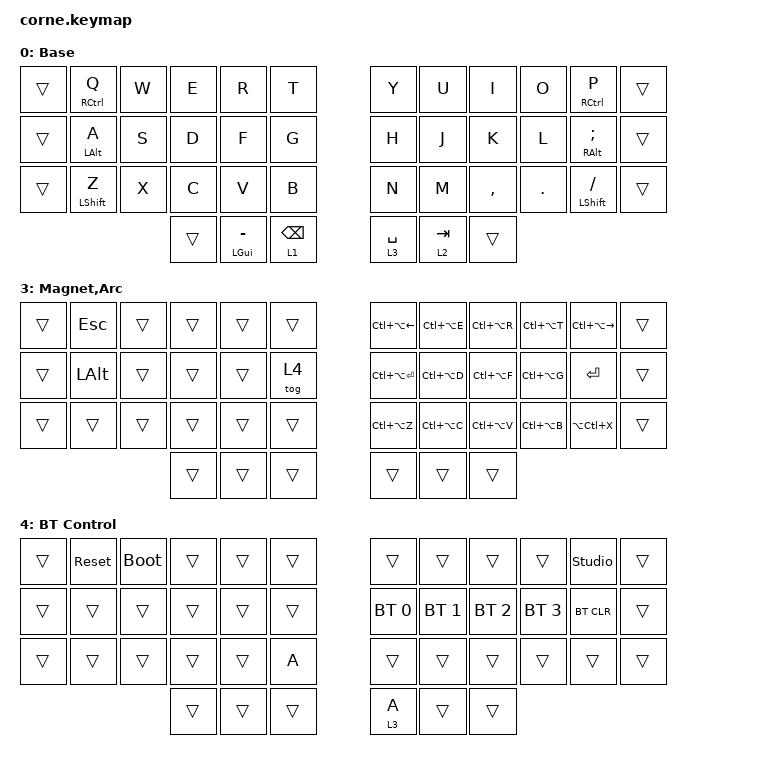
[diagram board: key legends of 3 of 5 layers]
/*
 * Copyright (c) 2020 The ZMK Contributors
 *
 * SPDX-License-Identifier: MIT
 */
//Layers 

#define Base 0
#define Lower 1
#define Raise 2
#define Funct 3

// #define block
// #define SCSH &kp LS(LG(NUMBER_4))

#include <behaviors.dtsi>
#include <dt-bindings/zmk/bt.h>
#include <dt-bindings/zmk/keys.h>

&mt {
    tapping-term-ms = <150>;

    // require-prior-idle-ms = <50>;
};

&lt {
    tapping-term-ms = <150>;

    //require-prior-idle-ms = <125>; 
};

/ {
    behaviors {
        lslc: lslc {
            compatible = "zmk,behavior-tap-dance";
            label = "LSLC";
            #binding-cells = <0>;
            tapping-term-ms = <200>;
            bindings = <&kp LEFT_SHIFT>, <&kp LCTRL>;
        };

        rsra: rsra {
            compatible = "zmk,behavior-tap-dance";
            label = "RSRA";
            #binding-cells = <0>;
            tapping-term-ms = <200>;
            bindings = <&kp RIGHT_SHIFT>, <&kp RALT>;
        };

        long_MT: long_MT {
            compatible = "zmk,behavior-hold-tap";
            label = "LONG_MT";
            bindings = <&kp>, <&kp>;

            require-prior-idle-ms = <125>;
            #binding-cells = <2>;
            tapping-term-ms = <300>;
            quick-tap-ms = <0>;
            flavor = "tap-preferred";
        };

        short_LT: short_LT {
            compatible = "zmk,behavior-hold-tap";
            label = "SHORT_LT";
            bindings = <&mo>, <&kp>;

            #binding-cells = <2>;
            tapping-term-ms = <85>;
            quick-tap-ms = <0>;

            //flavor = "hold-preferred";
        };
    };

    macros {
        ae: ae {
            compatible = "zmk,behavior-macro";
            label = "AE";
            #binding-cells = <0>;
            bindings = <&kp DOUBLE_QUOTES &kp A>;
        };

        oe: oe {
            compatible = "zmk,behavior-macro";
            label = "OE";
            #binding-cells = <0>;
            bindings = <&kp DOUBLE_QUOTES &kp O>;
        };

        ue: ue {
            compatible = "zmk,behavior-macro";
            label = "UE";
            #binding-cells = <0>;
            bindings = <&kp DOUBLE_QUOTES &kp U>;
        };
    };
    combos {
        compatible = "zmk,combos";
    };

    keymap {
        compatible = "zmk,keymap";

         default_layer {
            label = "Base";
            bindings = <
&trans &long_MT RIGHT_CONTROL Q  &kp W  &kp E  &kp R               &kp T              &kp Y        &kp U            &kp I      &kp O    &long_MT RCTRL P &trans 
&trans &long_MT LEFT_ALT A       &kp S  &kp D  &kp F               &kp G              &kp H        &kp J            &kp K      &kp L    &long_MT RIGHT_ALT SEMICOLON &trans 
&trans &mt LEFT_SHIFT Z          &kp X  &kp C  &kp V               &kp B              &kp N        &kp M            &kp COMMA  &kp DOT  &mt LEFT_SHIFT SLASH &trans 
                                        &trans &mt LEFT_GUI MINUS  &lt 1 BACKSPACE    &lt 3 SPACE  &short_LT 2 TAB &trans 
            >;
        };

        layer_1 {
            label = "Num,Arrow";
            bindings = <
 &trans &kp ESCAPE      &kp LG(ESCAPE)     &kp UP_ARROW     &kp LC(LA(LG(C)))     &kp TILDE                       &kp SQT            &kp NUMBER_1  &kp NUMBER_2  &kp NUMBER_3  &kp PLUS &trans 
 &trans &kp LEFT_GUI    &kp LEFT           &kp DOWN         &kp RIGHT             &kp LG(BACKSPACE)               &kp DOUBLE_QUOTES  &kp NUMBER_4  &kp N5        &kp NUMBER_6  &kp MINUS &trans 
 &trans &kp LEFT_SHIFT  &kp K_VOLUME_DOWN  &kp K_VOLUME_UP  &kp LS(LG(NUMBER_4))  &kp LA(LS(LC(LG(NUMBER_1))))    &kp GRAVE          &kp N7        &kp N8        &kp NUMBER_9  &kp EQUAL &trans 
                                                   &trans   &trans                &trans                          &kp DEL            &kp NUMBER_0 &trans 
       &trans      >;
        };

        layer_2 {
            label = "Sym,Nav,CTRL";
            bindings = <
 &trans &kp EXCLAMATION  &kp AT_SIGN  &kp HASH           &kp DLLR          &kp PRCNT               &kp CARET  &kp AMPS      &kp KP_MULTIPLY  &kp LPAR  &kp RPAR &trans 
 &trans &ae              &kp RA(S)    &oe                &ue               &kp LS(LA(NUMBER_2))    &kp TILDE  &kp LA(LEFT)  &kp LA(RIGHT)    &kp LBKT  &kp RBKT &trans 
 &trans &kp LSHFT        &kp A        &kp LS(LA(LG(C)))  &kp LS(LG(SEMI))  &kp LS(LA(LG(K)))       &trans     &kp LG(LEFT)  &kp LG(RIGHT)    &kp LBRC  &kp RBRC &trans 
                                             &trans      &kp LC(TAB)       &kp LG(BACKSPACE)       &trans     &trans &trans 
            >;
        };

        layer_3 {
            label = "Magnet,Arc";
            bindings = <
 &trans &kp ESCAPE    &trans  &trans  &trans  &trans    &kp LC(LA(LEFT))    &kp LC(LA(E))  &kp LC(LA(R))  &kp LC(LA(T))  &kp LC(LA(RIGHT)) &trans 
 &trans &kp LEFT_ALT  &trans  &trans  &trans  &tog 4    &kp LC(LA(RETURN))  &kp LC(LA(D))  &kp LC(LA(F))  &kp LC(LA(G))  &kp RETURN &trans 
 &trans &trans        &trans  &trans  &trans &trans   &kp LC(LA(Z))       &kp LC(LA(C))  &kp LC(LA(V))  &kp LC(LA(B))  &kp LA(LC(X)) &trans 
                            &trans    &trans  &trans    &trans              &trans &trans 
            >;
        };

        layer_4 {
            label = "BT Control";
            bindings = <
 &trans &sys_reset  &bootloader  &trans  &trans  &trans    &trans        &trans        &trans        &trans        &studio_unlock &trans 
 &trans &trans      &trans       &trans  &trans  &trans    &bt BT_SEL 0  &bt BT_SEL 1  &bt BT_SEL 2  &bt BT_SEL 3  &bt BT_CLR &trans 
 &trans &trans      &trans       &trans  &trans  &kp A     &trans        &trans        &trans        &trans        &trans &trans 
                                 &trans  &trans  &trans    &lt 3 A        &trans &trans 
            >;
        };
    };
};
